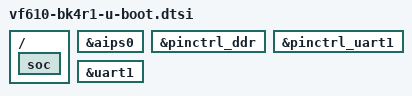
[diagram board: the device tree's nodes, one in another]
// SPDX-License-Identifier: (GPL-2.0+ OR MIT)
/*
 * Copyright 2019
 * Lukasz Majewski, DENX Software Engineering, lukma@denx.de
 */

/ {
	soc {
		u-boot,dm-all;
	};
};

&aips0 {
	u-boot,dm-all;
};

&pinctrl_ddr {
	u-boot,dm-all;
};

&pinctrl_uart1 {
	u-boot,dm-all;
};

&uart1 {
	u-boot,dm-all;
};
